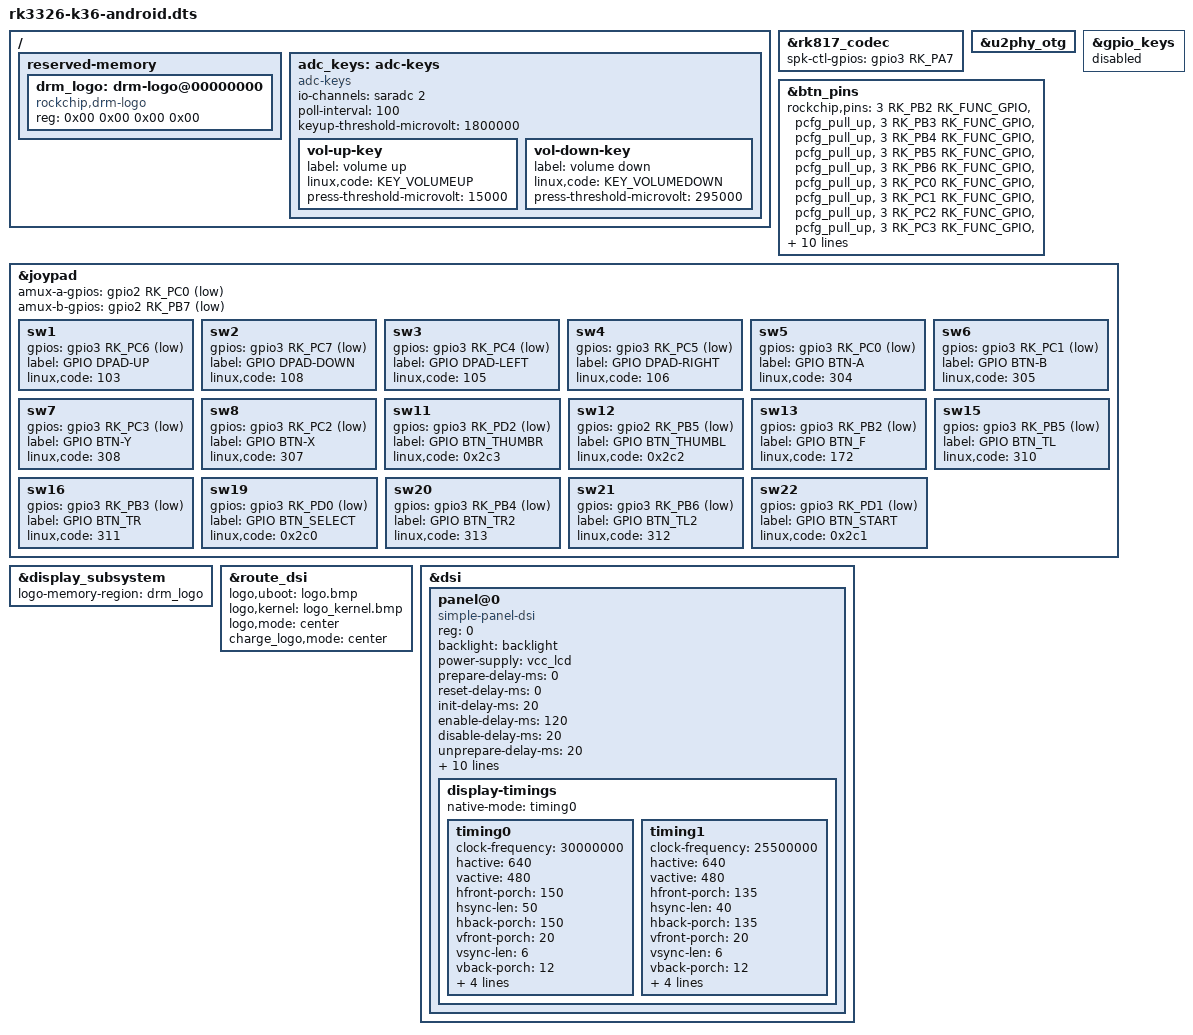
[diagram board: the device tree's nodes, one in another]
// SPDX-License-Identifier: (GPL-2.0+ OR MIT)
/*
 * K36 portable gaming console - Android DTB
 * HX8394 MIPI DSI panel, 640x480
 */

/dts-v1/;
#include "rk3326-r36s-android.dtsi"

/* K36 speaker amp enable on gpio3 PA7 */
&rk817_codec {
	spk-ctl-gpios = <&gpio3 RK_PA7 GPIO_ACTIVE_HIGH>;
};

/* K36 USB OTG port — enable PHY for ADB/USB device mode */
&u2phy_otg {
	status = "okay";
};

/* K36 uses ADC for volume buttons, not GPIO */
&gpio_keys {
	status = "disabled";
};

/ {
	reserved-memory {
		drm_logo: drm-logo@00000000 {
			compatible = "rockchip,drm-logo";
			reg = <0x00 0x00 0x00 0x00>;
		};
	};

	adc_keys: adc-keys {
		compatible = "adc-keys";
		io-channels = <&saradc 2>;
		io-channel-names = "buttons";
		poll-interval = <100>;
		keyup-threshold-microvolt = <1800000>;

		vol-up-key {
			label = "volume up";
			linux,code = <KEY_VOLUMEUP>;
			press-threshold-microvolt = <15000>;
		};

		vol-down-key {
			label = "volume down";
			linux,code = <KEY_VOLUMEDOWN>;
			press-threshold-microvolt = <295000>;
		};
	};
};

/*
 * K36 button GPIOs are on gpio3/gpio2, not gpio1 as on R36S.
 * Pinctrl: update btn_pins to K36's actual button pins.
 */
&btn_pins {
	rockchip,pins =
		<3 RK_PB2 RK_FUNC_GPIO &pcfg_pull_up>,
		<3 RK_PB3 RK_FUNC_GPIO &pcfg_pull_up>,
		<3 RK_PB4 RK_FUNC_GPIO &pcfg_pull_up>,
		<3 RK_PB5 RK_FUNC_GPIO &pcfg_pull_up>,
		<3 RK_PB6 RK_FUNC_GPIO &pcfg_pull_up>,
		<3 RK_PC0 RK_FUNC_GPIO &pcfg_pull_up>,
		<3 RK_PC1 RK_FUNC_GPIO &pcfg_pull_up>,
		<3 RK_PC2 RK_FUNC_GPIO &pcfg_pull_up>,
		<3 RK_PC3 RK_FUNC_GPIO &pcfg_pull_up>,
		<3 RK_PC4 RK_FUNC_GPIO &pcfg_pull_up>,
		<3 RK_PC5 RK_FUNC_GPIO &pcfg_pull_up>,
		<3 RK_PC6 RK_FUNC_GPIO &pcfg_pull_up>,
		<3 RK_PC7 RK_FUNC_GPIO &pcfg_pull_up>,
		<3 RK_PD0 RK_FUNC_GPIO &pcfg_pull_up>,
		<3 RK_PD1 RK_FUNC_GPIO &pcfg_pull_up>,
		<3 RK_PD2 RK_FUNC_GPIO &pcfg_pull_up>,
		<3 RK_PD3 RK_FUNC_GPIO &pcfg_pull_up>,
		<2 RK_PB5 RK_FUNC_GPIO &pcfg_pull_up>;
		/* gpio2 PB6 (pin14) omitted: conflicts with uart2-m1 RX */
};

/* K36 analog mux is on gpio2, different select pins and channel order */
&joypad {
	amux-a-gpios = <&gpio2 RK_PC0 GPIO_ACTIVE_LOW>;
	amux-b-gpios = <&gpio2 RK_PB7 GPIO_ACTIVE_LOW>;
	/* amux-en on gpio2 PB4 conflicts with uart2-m1 TX — omit, mux always enabled */

	sw1 {
		gpios = <&gpio3 RK_PC6 GPIO_ACTIVE_LOW>;
		label = "GPIO DPAD-UP";
		linux,code = <103>;
	};
	sw2 {
		gpios = <&gpio3 RK_PC7 GPIO_ACTIVE_LOW>;
		label = "GPIO DPAD-DOWN";
		linux,code = <108>;
	};
	sw3 {
		gpios = <&gpio3 RK_PC4 GPIO_ACTIVE_LOW>;
		label = "GPIO DPAD-LEFT";
		linux,code = <105>;
	};
	sw4 {
		gpios = <&gpio3 RK_PC5 GPIO_ACTIVE_LOW>;
		label = "GPIO DPAD-RIGHT";
		linux,code = <106>;
	};
	sw5 {
		gpios = <&gpio3 RK_PC0 GPIO_ACTIVE_LOW>;
		label = "GPIO BTN-A";
		linux,code = <304>;
	};
	sw6 {
		gpios = <&gpio3 RK_PC1 GPIO_ACTIVE_LOW>;
		label = "GPIO BTN-B";
		linux,code = <305>;
	};
	sw7 {
		gpios = <&gpio3 RK_PC3 GPIO_ACTIVE_LOW>;
		label = "GPIO BTN-Y";
		linux,code = <308>;
	};
	sw8 {
		gpios = <&gpio3 RK_PC2 GPIO_ACTIVE_LOW>;
		label = "GPIO BTN-X";
		linux,code = <307>;
	};
	sw11 {
		/* gpio2 PB6 conflicts with uart2-m1 RX — disabled */
		gpios = <&gpio3 RK_PD2 GPIO_ACTIVE_LOW>;
		label = "GPIO BTN_THUMBR";
		linux,code = <0x2c3>;
	};
	sw12 {
		gpios = <&gpio2 RK_PB5 GPIO_ACTIVE_LOW>;
		label = "GPIO BTN_THUMBL";
		linux,code = <0x2c2>;
	};
	sw13 {
		gpios = <&gpio3 RK_PB2 GPIO_ACTIVE_LOW>;
		label = "GPIO BTN_F";
		linux,code = <172>;
	};
	sw15 {
		gpios = <&gpio3 RK_PB5 GPIO_ACTIVE_LOW>;
		label = "GPIO BTN_TL";
		linux,code = <310>;
	};
	sw16 {
		gpios = <&gpio3 RK_PB3 GPIO_ACTIVE_LOW>;
		label = "GPIO BTN_TR";
		linux,code = <311>;
	};
	sw19 {
		gpios = <&gpio3 RK_PD0 GPIO_ACTIVE_LOW>;
		label = "GPIO BTN_SELECT";
		linux,code = <0x2c0>;
	};
	sw20 {
		gpios = <&gpio3 RK_PB4 GPIO_ACTIVE_LOW>;
		label = "GPIO BTN_TR2";
		linux,code = <313>;
	};
	sw21 {
		gpios = <&gpio3 RK_PB6 GPIO_ACTIVE_LOW>;
		label = "GPIO BTN_TL2";
		linux,code = <312>;
	};
	sw22 {
		gpios = <&gpio3 RK_PD1 GPIO_ACTIVE_LOW>;
		label = "GPIO BTN_START";
		linux,code = <0x2c1>;
	};
};

&display_subsystem {
	logo-memory-region = <&drm_logo>;
};

&route_dsi {
	logo,uboot = "logo.bmp";
	logo,kernel = "logo_kernel.bmp";
	logo,mode = "center";
	charge_logo,mode = "center";
	status = "okay";
};

&dsi {
	panel@0 {
		compatible = "simple-panel-dsi";
		reg = <0>;

		backlight = <&backlight>;
		power-supply = <&vcc_lcd>;

		/*
		 * No reset-gpios: kernel must not reset the panel.
		 * U-Boot fully initialises HX8394 before handing off;
		 * the kernel just needs to wake it (sleep-out + display-on).
		 * enable-gpios also omitted — U-Boot leaves PB5 HIGH.
		 */
		prepare-delay-ms = <0>;
		reset-delay-ms = <0>;
		init-delay-ms = <20>;
		enable-delay-ms = <120>;
		disable-delay-ms = <20>;
		unprepare-delay-ms = <20>;

		width-mm = <153>;
		height-mm = <85>;

		dsi,flags = <(MIPI_DSI_MODE_VIDEO           |
			      MIPI_DSI_MODE_VIDEO_BURST     |
			      MIPI_DSI_MODE_LPM             |
			      MIPI_DSI_MODE_EOT_PACKET)>;

		dsi,format = <MIPI_DSI_FMT_RGB888>;
		dsi,lanes = <4>;

		/* Minimal sequence: panel already init'd by U-Boot, just wake it */
		panel-init-sequence = [
			05 78 01 11
			05 14 01 29
		];

		panel-exit-sequence = [
			05 00 01 28
			05 00 01 10
		];

		display-timings {
			native-mode = <&timing0>;

			timing0 {
				clock-frequency = <30000000>;
				hactive = <640>;
				vactive = <480>;
				hfront-porch = <150>;
				hsync-len = <50>;
				hback-porch = <150>;
				vfront-porch = <20>;
				vsync-len = <6>;
				vback-porch = <12>;
				hsync-active = <0>;
				vsync-active = <0>;
				de-active = <0>;
				pixelclk-active = <0>;
			};

			timing1 {
				clock-frequency = <25500000>;
				hactive = <640>;
				vactive = <480>;
				hfront-porch = <135>;
				hsync-len = <40>;
				hback-porch = <135>;
				vfront-porch = <20>;
				vsync-len = <6>;
				vback-porch = <12>;
				hsync-active = <0>;
				vsync-active = <0>;
				de-active = <0>;
				pixelclk-active = <0>;
			};
		};
	};
};
